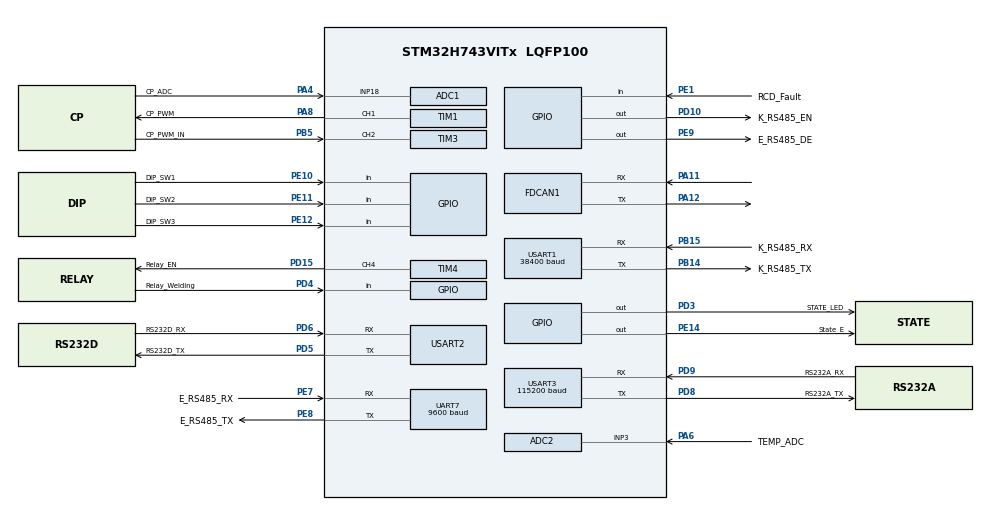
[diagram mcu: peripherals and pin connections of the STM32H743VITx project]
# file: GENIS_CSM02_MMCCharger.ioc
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ADC1.Channel-0\#ChannelRegularConversion=ADC_CHANNEL_18
ADC1.NbrOfConversionFlag=1
ADC1.OffsetNumber-0\#ChannelRegularConversion=ADC_OFFSET_NONE
ADC1.OffsetSignedSaturation-0\#ChannelRegularConversion=DISABLE
ADC1.Rank-0\#ChannelRegularConversion=1
ADC1.SamplingTime-0\#ChannelRegularConversion=ADC_SAMPLETIME_810CYCLES_5
ADC1.master=1
ADC2.Channel-6\#ChannelRegularConversion=ADC_CHANNEL_3
ADC2.ContinuousConvMode=DISABLE
ADC2.ConversionDataManagement=ADC_CONVERSIONDATA_DR
ADC2.DiscontinuousConvMode=DISABLE
ADC2.NbrOfConversionFlag=1
ADC2.OffsetNumber-6\#ChannelRegularConversion=ADC_OFFSET_NONE
ADC2.OffsetSignedSaturation-6\#ChannelRegularConversion=DISABLE
ADC2.Overrun=ADC_OVR_DATA_PRESERVED
ADC2.Rank-6\#ChannelRegularConversion=1
ADC2.SamplingTime-6\#ChannelRegularConversion=ADC_SAMPLETIME_810CYCLES_5
CORTEX_M7.AccessPermission_Spec=MPU_REGION_FULL_ACCESS
CORTEX_M7.BaseAddress_Spec=0x30000000
CORTEX_M7.CPU_DCache=Enabled
CORTEX_M7.CPU_ICache=Enabled
CORTEX_M7.IsShareable_Spec=MPU_ACCESS_NOT_SHAREABLE
CORTEX_M7.Size_Spec=MPU_REGION_SIZE_256KB
CORTEX_M7.SubRegionDisable_Spec=0x00
CORTEX_M7.TypeExtField_Spec=MPU_TEX_LEVEL1
CORTEX_M7.default_mode_Activation=1
FDCAN1.AutoRetransmission=ENABLE
FDCAN1.CalculateBaudRateNominal=500000
FDCAN1.CalculateTimeBitNominal=2000
FDCAN1.CalculateTimeQuantumNominal=200.0
FDCAN1.DataPrescaler=15
FDCAN1.DataSyncJumpWidth=1
FDCAN1.DataTimeSeg1=5
FDCAN1.DataTimeSeg2=4
FDCAN1.ExtFiltersNbr=1
FDCAN1.Mode=FDCAN_MODE_NORMAL
FDCAN1.NominalPrescaler=15
FDCAN1.NominalSyncJumpWidth=1
FDCAN1.NominalTimeSeg1=5
FDCAN1.NominalTimeSeg2=4
FDCAN1.ProtocolException=ENABLE
FDCAN1.RxFifo0ElmtsNbr=1
FDCAN1.StdFiltersNbr=0
FDCAN1.TxBuffersNbr=1
FDCAN1.TxFifoQueueElmtsNbr=1
FREERTOS.Tasks01=defaultTask,24,2048,StartDefaultTask,Default,NULL,Dynamic,NULL,NULL;Task_CANTx,8,2048,CANTxControl_Task,Default,NULL,Dynamic,NULL,NULL;Task_CANRx,8,2048,CANRxControl_Task,Default,NULL,Dynamic,NULL,NULL
FREERTOS.configCHECK_FOR_STACK_OVERFLOW=2
FREERTOS.configENABLE_FPU=1
FREERTOS.configTOTAL_HEAP_SIZE=102768
FREERTOS.configUSE_NEWLIB_REENTRANT=1
Mcu.Family=STM32H7
Mcu.Name=STM32H743VITx
Mcu.Package=LQFP100
NVIC.ADC_IRQn=true\:5\:0\:false\:false\:true\:true\:true\:true\:true
NVIC.FDCAN1_IT0_IRQn=true\:5\:0\:false\:false\:true\:true\:true\:true\:true
NVIC.FDCAN1_IT1_IRQn=true\:5\:0\:false\:false\:true\:true\:true\:true\:true
NVIC.FDCAN_CAL_IRQn=true\:5\:0\:false\:false\:true\:true\:true\:true\:true
NVIC.PriorityGroup=NVIC_PRIORITYGROUP_4
NVIC.TIM2_IRQn=true\:15\:0\:false\:false\:true\:false\:false\:true\:true
NVIC.TimeBase=TIM2_IRQn
NVIC.TimeBaseIP=TIM2
NVIC.UART7_IRQn=true\:5\:0\:false\:false\:true\:true\:true\:true\:true
NVIC.USART1_IRQn=true\:5\:0\:false\:false\:true\:true\:true\:true\:true
NVIC.USART2_IRQn=true\:5\:0\:true\:false\:true\:true\:true\:true\:true
NVIC.USART3_IRQn=true\:5\:0\:false\:false\:true\:true\:true\:true\:true
PA11.Mode=FDCAN_Activate
PA11.Signal=FDCAN1_RX
PA12.Mode=FDCAN_Activate
PA12.Signal=FDCAN1_TX
PA13\ (JTMS/SWDIO).Mode=JTAG_5_pins
PA13\ (JTMS/SWDIO).Signal=DEBUG_JTMS-SWDIO
PA14\ (JTCK/SWCLK).Mode=JTAG_5_pins
PA14\ (JTCK/SWCLK).Signal=DEBUG_JTCK-SWCLK
PA15\ (JTDI).Mode=JTAG_5_pins
PA15\ (JTDI).Signal=DEBUG_JTDI
PA4.GPIO_Label=CP_ADC
PA4.Signal=ADCx_INP18
PA6.GPIO_Label=TEMP_ADC
PA6.Signal=ADCx_INP3
PA8.GPIO_Label=CP_PWM
PA8.Signal=S_TIM1_CH1
PB14.GPIO_Label=K_RS485_TX
PB14.Mode=Asynchronous
PB14.Signal=USART1_TX
PB15.GPIO_Label=K_RS485_RX
PB15.Mode=Asynchronous
PB15.Signal=USART1_RX
PB3\ (JTDO/TRACESWO).Mode=JTAG_5_pins
PB3\ (JTDO/TRACESWO).Signal=DEBUG_JTDO-SWO
PB4\ (NJTRST).Mode=JTAG_5_pins
PB4\ (NJTRST).Signal=DEBUG_JTRST
PB5.GPIO_Label=CP_PWM_IN
PB5.Signal=S_TIM3_CH2
PC14-OSC32_IN\ (OSC32_IN).Mode=LSE-External-Oscillator
PC14-OSC32_IN\ (OSC32_IN).Signal=RCC_OSC32_IN
PC15-OSC32_OUT\ (OSC32_OUT).Mode=LSE-External-Oscillator
PC15-OSC32_OUT\ (OSC32_OUT).Signal=RCC_OSC32_OUT
PD10.GPIO_Label=K_RS485_EN
PD10.Signal=GPIO_Output
PD15.GPIO_Label=Relay_EN
PD15.Signal=S_TIM4_CH4
PD3.GPIO_Label=STATE_LED
PD3.Signal=GPIO_Output
PD4.GPIO_Label=Relay_Welding
PD4.Signal=GPIO_Input
PD5.GPIO_Label=RS232D_TX
PD5.Mode=Asynchronous
PD5.Signal=USART2_TX
PD6.GPIO_Label=RS232D_RX
PD6.Mode=Asynchronous
PD6.Signal=USART2_RX
PD8.GPIO_Label=RS232A_TX
PD8.Mode=Asynchronous
PD8.Signal=USART3_TX
PD9.GPIO_Label=RS232A_RX
PD9.Mode=Asynchronous
PD9.Signal=USART3_RX
PE1.GPIO_Label=RCD_Fault
PE1.GPIO_PuPd=GPIO_PULLDOWN
PE1.Signal=GPIO_Input
PE10.GPIO_Label=DIP_SW1
PE10.Signal=GPIO_Input
PE11.GPIO_Label=DIP_SW2
PE11.Signal=GPIO_Input
PE12.GPIO_Label=DIP_SW3
PE12.Signal=GPIO_Input
PE14.GPIO_Label=State_E
PE14.Signal=GPIO_Output
PE7.GPIO_Label=E_RS485_RX
PE7.Mode=Asynchronous
PE7.Signal=UART7_RX
PE8.GPIO_Label=E_RS485_TX
PE8.Mode=Asynchronous
PE8.Signal=UART7_TX
PE9.GPIO_Label=E_RS485_DE
PE9.Signal=GPIO_Output
PH0-OSC_IN\ (PH0).Mode=HSE-External-Oscillator
PH0-OSC_IN\ (PH0).Signal=RCC_OSC_IN
PH1-OSC_OUT\ (PH1).Mode=HSE-External-Oscillator
PH1-OSC_OUT\ (PH1).Signal=RCC_OSC_OUT
ProjectManager.HeapSize=0x200
ProjectManager.StackSize=0x400
ProjectManager.TargetToolchain=STM32CubeIDE
RCC.ADCFreq_Value=75000000
RCC.APB1Freq_Value=120000000
RCC.APB2Freq_Value=120000000
RCC.APB3Freq_Value=120000000
RCC.APB4Freq_Value=120000000
RCC.CortexFreq_Value=480000000
RCC.D1PPRE=RCC_APB3_DIV2
RCC.D2PPRE1=RCC_APB1_DIV2
RCC.D2PPRE2=RCC_APB2_DIV2
RCC.D3PPRE=RCC_APB4_DIV2
RCC.DIVM1=1
RCC.DIVM2=1
RCC.DIVN1=60
RCC.DIVN2=9
RCC.DIVQ1=8
RCC.FDCANCLockSelection=RCC_FDCANCLKSOURCE_PLL2
RCC.HCLKFreq_Value=240000000
RCC.HPRE=RCC_HCLK_DIV2
RCC.HSE_VALUE=16000000
RCC.PLL2FRACN=3072
RCC.PLLFRACN=0
RCC.PLLSourceVirtual=RCC_PLLSOURCE_HSE
RCC.PWR_Regulator_Voltage_Scale=PWR_REGULATOR_VOLTAGE_SCALE0
RCC.RTCClockSelection=RCC_RTCCLKSOURCE_LSE
RCC.SYSCLKFreq_VALUE=480000000
RCC.SYSCLKSource=RCC_SYSCLKSOURCE_PLLCLK
RCC.USBFreq_Value=120000000
SH.ADCx_INP18.0=ADC1_INP18,IN18-Single-Ended
SH.ADCx_INP3.0=ADC2_INP3,IN3-Single-Ended
SH.S_TIM1_CH1.0=TIM1_CH1,PWM Generation1 CH1
SH.S_TIM3_CH2.0=TIM3_CH2,PWM_Input_2
SH.S_TIM4_CH4.0=TIM4_CH4,PWM Generation4 CH4
TIM1.Channel-PWM\ Generation1\ CH1=TIM_CHANNEL_1
TIM1.Period=998
TIM1.Prescaler=240
TIM4.Channel-PWM\ Generation4\ CH4=TIM_CHANNEL_4
TIM4.Period=1000-1
TIM4.Prescaler=12-1
TIM4.Pulse-PWM\ Generation4\ CH4=0
TIM4.TIM_MasterOutputTrigger=TIM_TRGO_UPDATE
UART7.BaudRate=9600
USART1.BaudRate=38400
USART1.VirtualMode-Asynchronous=VM_ASYNC
USART2.VirtualMode-Asynchronous=VM_ASYNC
USART3.BaudRate=115200
USART3.VirtualMode-Asynchronous=VM_ASYNC
VP_FREERTOS_VS_CMSIS_V2.Mode=CMSIS_V2
VP_RTC_VS_RTC_Activate.Mode=RTC_Enabled
VP_SYS_VS_tim2.Mode=TIM2
board=custom

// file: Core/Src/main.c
/* USER CODE BEGIN Header */
/**
  ******************************************************************************
  * @file           : main.c
  * @brief          : Main program body
  ******************************************************************************
  * @attention
  *
  * Copyright (c) 2025 STMicroelectronics.
  * All rights reserved.
  *
  * This software is licensed under terms that can be found in the LICENSE file
  * in the root directory of this software component.
  * If no LICENSE file comes with this software, it is provided AS-IS.
  *
  ******************************************************************************
  */
/* USER CODE END Header */
#include "main.h"
#include "cmsis_os.h"
#include "adc.h"
#include "fdcan.h"
#include "rtc.h"
#include "tim.h"
#include "usart.h"
#include "gpio.h"

/* USER CODE BEGIN Includes */
#include "../Driver/UART.h"
/* USER CODE END Includes */

void SystemClock_Config(void);
void PeriphCommonClock_Config(void);
static void MPU_Config(void);
void MX_FREERTOS_Init(void);

int main(void)
{

  /* MPU Configuration--------------------------------------------------------*/
  MPU_Config();

  /* Enable the CPU Cache */

  /* Enable I-Cache---------------------------------------------------------*/
  SCB_EnableICache();

  /* Enable D-Cache---------------------------------------------------------*/
  SCB_EnableDCache();

  /* MCU Configuration--------------------------------------------------------*/

  /* Reset of all peripherals, Initializes the Flash interface and the Systick. */
  HAL_Init();

  /* USER CODE BEGIN Init */
  HAL_UART_Receive_IT(&huart2, &uart2RxData, 1);
  /* USER CODE END Init */

  /* Configure the system clock */
  SystemClock_Config();

  /* Configure the peripherals common clocks */
  PeriphCommonClock_Config();

  /* Initialize all configured peripherals */
  MX_GPIO_Init();
  MX_UART7_Init();
  MX_USART1_UART_Init();
  MX_USART2_UART_Init();
  MX_USART3_UART_Init();
  MX_TIM4_Init();
  MX_ADC1_Init();
  MX_TIM1_Init();
  MX_TIM3_Init();
  MX_RTC_Init();
  MX_ADC2_Init();
  MX_FDCAN1_Init();

  /* Init scheduler */
  osKernelInitialize();

  /* Call init function for freertos objects (in cmsis_os2.c) */
  MX_FREERTOS_Init();

  /* Start scheduler */
  osKernelStart();

  /* We should never get here as control is now taken by the scheduler */

  /* Infinite loop */
  while (1)
  {

  }
}

void SystemClock_Config(void)
{
  RCC_OscInitTypeDef RCC_OscInitStruct = {0};
  RCC_ClkInitTypeDef RCC_ClkInitStruct = {0};

  /** Supply configuration update enable
  */
  HAL_PWREx_ConfigSupply(PWR_LDO_SUPPLY);

  /** Configure the main internal regulator output voltage
  */
  __HAL_PWR_VOLTAGESCALING_CONFIG(PWR_REGULATOR_VOLTAGE_SCALE0);

  while(!__HAL_PWR_GET_FLAG(PWR_FLAG_VOSRDY)) {}

  /** Configure LSE Drive Capability
  */
  HAL_PWR_EnableBkUpAccess();
  __HAL_RCC_LSEDRIVE_CONFIG(RCC_LSEDRIVE_LOW);

  /** Initializes the RCC Oscillators according to the specified parameters
  * in the RCC_OscInitTypeDef structure.
  */
  RCC_OscInitStruct.OscillatorType = RCC_OSCILLATORTYPE_HSE|RCC_OSCILLATORTYPE_LSE;
  RCC_OscInitStruct.HSEState = RCC_HSE_ON;
  RCC_OscInitStruct.LSEState = RCC_LSE_ON;
  RCC_OscInitStruct.PLL.PLLState = RCC_PLL_ON;
  RCC_OscInitStruct.PLL.PLLSource = RCC_PLLSOURCE_HSE;
  RCC_OscInitStruct.PLL.PLLM = 1;
  RCC_OscInitStruct.PLL.PLLN = 60;
  RCC_OscInitStruct.PLL.PLLP = 2;
  RCC_OscInitStruct.PLL.PLLQ = 8;
  RCC_OscInitStruct.PLL.PLLR = 2;
  RCC_OscInitStruct.PLL.PLLRGE = RCC_PLL1VCIRANGE_3;
  RCC_OscInitStruct.PLL.PLLVCOSEL = RCC_PLL1VCOWIDE;
  RCC_OscInitStruct.PLL.PLLFRACN = 0;
  if (HAL_RCC_OscConfig(&RCC_OscInitStruct) != HAL_OK)
  {
    Error_Handler();
  }

  /** Initializes the CPU, AHB and APB buses clocks
  */
  RCC_ClkInitStruct.ClockType = RCC_CLOCKTYPE_HCLK|RCC_CLOCKTYPE_SYSCLK
                              |RCC_CLOCKTYPE_PCLK1|RCC_CLOCKTYPE_PCLK2
                              |RCC_CLOCKTYPE_D3PCLK1|RCC_CLOCKTYPE_D1PCLK1;
  RCC_ClkInitStruct.SYSCLKSource = RCC_SYSCLKSOURCE_PLLCLK;
  RCC_ClkInitStruct.SYSCLKDivider = RCC_SYSCLK_DIV1;
  RCC_ClkInitStruct.AHBCLKDivider = RCC_HCLK_DIV2;
  RCC_ClkInitStruct.APB3CLKDivider = RCC_APB3_DIV2;
  RCC_ClkInitStruct.APB1CLKDivider = RCC_APB1_DIV2;
  RCC_ClkInitStruct.APB2CLKDivider = RCC_APB2_DIV2;
  RCC_ClkInitStruct.APB4CLKDivider = RCC_APB4_DIV2;

  if (HAL_RCC_ClockConfig(&RCC_ClkInitStruct, FLASH_LATENCY_4) != HAL_OK)
  {
    Error_Handler();
  }
}

void PeriphCommonClock_Config(void)
{
  RCC_PeriphCLKInitTypeDef PeriphClkInitStruct = {0};

  /** Initializes the peripherals clock
  */
  PeriphClkInitStruct.PeriphClockSelection = RCC_PERIPHCLK_ADC|RCC_PERIPHCLK_FDCAN;
  PeriphClkInitStruct.PLL2.PLL2M = 1;
  PeriphClkInitStruct.PLL2.PLL2N = 9;
  PeriphClkInitStruct.PLL2.PLL2P = 2;
  PeriphClkInitStruct.PLL2.PLL2Q = 2;
  PeriphClkInitStruct.PLL2.PLL2R = 2;
  PeriphClkInitStruct.PLL2.PLL2RGE = RCC_PLL2VCIRANGE_3;
  PeriphClkInitStruct.PLL2.PLL2VCOSEL = RCC_PLL2VCOMEDIUM;
  PeriphClkInitStruct.PLL2.PLL2FRACN = 3072;
  PeriphClkInitStruct.FdcanClockSelection = RCC_FDCANCLKSOURCE_PLL2;
  PeriphClkInitStruct.AdcClockSelection = RCC_ADCCLKSOURCE_PLL2;
  if (HAL_RCCEx_PeriphCLKConfig(&PeriphClkInitStruct) != HAL_OK)
  {
    Error_Handler();
  }
}

 /* MPU Configuration */

void MPU_Config(void)
{
  MPU_Region_InitTypeDef MPU_InitStruct = {0};

  /* Disables the MPU */
  HAL_MPU_Disable();

  /** Initializes and configures the Region and the memory to be protected
  */
  MPU_InitStruct.Enable = MPU_REGION_ENABLE;
  MPU_InitStruct.Number = MPU_REGION_NUMBER0;
  MPU_InitStruct.BaseAddress = 0x30000000;
  MPU_InitStruct.Size = MPU_REGION_SIZE_256KB;
  MPU_InitStruct.SubRegionDisable = 0x00;
  MPU_InitStruct.TypeExtField = MPU_TEX_LEVEL1;
  MPU_InitStruct.AccessPermission = MPU_REGION_FULL_ACCESS;
  MPU_InitStruct.DisableExec = MPU_INSTRUCTION_ACCESS_DISABLE;
  MPU_InitStruct.IsShareable = MPU_ACCESS_NOT_SHAREABLE;
  MPU_InitStruct.IsCacheable = MPU_ACCESS_NOT_CACHEABLE;
  MPU_InitStruct.IsBufferable = MPU_ACCESS_NOT_BUFFERABLE;

  HAL_MPU_ConfigRegion(&MPU_InitStruct);
  /* Enables the MPU */
  HAL_MPU_Enable(MPU_PRIVILEGED_DEFAULT);

}

void HAL_TIM_PeriodElapsedCallback(TIM_HandleTypeDef *htim)
{
  if (htim->Instance == TIM2)
  {
    HAL_IncTick();
  }
}

void Error_Handler(void)
{
  __disable_irq();
  while (1)
  {
  }
}

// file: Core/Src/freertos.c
/* USER CODE BEGIN Header */
/**
  ******************************************************************************
  * File Name          : freertos.c
  * Description        : Code for freertos applications
  ******************************************************************************
  * @attention
  *
  * Copyright (c) 2025 STMicroelectronics.
  * All rights reserved.
  *
  * This software is licensed under terms that can be found in the LICENSE file
  * in the root directory of this software component.
  * If no LICENSE file comes with this software, it is provided AS-IS.
  *
  ******************************************************************************
  */
/* USER CODE END Header */

#include "FreeRTOS.h"
#include "task.h"
#include "main.h"
#include "cmsis_os.h"

/* USER CODE BEGIN Includes */
#include "../Controller/CANController.h"
#include "../Genis/Charger/Charger.h"
/* USER CODE END Includes */

/* USER CODE BEGIN Variables */
  GenisCsm_ChargerType Charger = {0};
/* USER CODE END Variables */
/* Definitions for defaultTask */
osThreadId_t defaultTaskHandle;
const osThreadAttr_t defaultTask_attributes = {
  .name = "defaultTask",
  .stack_size = 2048 * 4,
  .priority = (osPriority_t) osPriorityNormal,
};
/* Definitions for Task_CANTx */
osThreadId_t Task_CANTxHandle;
const osThreadAttr_t Task_CANTx_attributes = {
  .name = "Task_CANTx",
  .stack_size = 2048 * 4,
  .priority = (osPriority_t) osPriorityLow,
};
/* Definitions for Task_CANRx */
osThreadId_t Task_CANRxHandle;
const osThreadAttr_t Task_CANRx_attributes = {
  .name = "Task_CANRx",
  .stack_size = 2048 * 4,
  .priority = (osPriority_t) osPriorityLow,
};

void StartDefaultTask(void *argument);
void CANTxControl_Task(void *argument);
void CANRxControl_Task(void *argument);

void MX_FREERTOS_Init(void); /* (MISRA C 2004 rule 8.1) */

/* Hook prototypes */
void vApplicationStackOverflowHook(xTaskHandle xTask, signed char *pcTaskName);

/* USER CODE BEGIN 4 */
void vApplicationStackOverflowHook(xTaskHandle xTask, signed char *pcTaskName)
{
   /* Run time stack overflow checking is performed if
   configCHECK_FOR_STACK_OVERFLOW is defined to 1 or 2. This hook function is
   called if a stack overflow is detected. */
}
/* USER CODE END 4 */

void MX_FREERTOS_Init(void) {

  /* Create the thread(s) */
  /* creation of defaultTask */
  defaultTaskHandle = osThreadNew(StartDefaultTask, NULL, &defaultTask_attributes);

  /* creation of Task_CANTx */
  Task_CANTxHandle = osThreadNew(CANTxControl_Task, NULL, &Task_CANTx_attributes);

  /* creation of Task_CANRx */
  Task_CANRxHandle = osThreadNew(CANRxControl_Task, NULL, &Task_CANRx_attributes);

}

void StartDefaultTask(void *argument)
{
  /* USER CODE BEGIN StartDefaultTask */

  GenisCsm_Charger_Init(&Charger);
  /* Infinite loop */
  for(;;)
  {
    GenisCsm_Charger_MainFunction(&Charger);
    osDelay(100);
  }
  /* USER CODE END StartDefaultTask */
}

void CANTxControl_Task(void *argument)
{
  /* USER CODE BEGIN CANTxControl_Task */
  FDCAN_Filter_Config_mask32_Init();
  /* Infinite loop */
  for(;;)
  {
    App_CanTxMainFunction(&Charger);
    osDelay(1);
  }
  /* USER CODE END CANTxControl_Task */
}

void CANRxControl_Task(void *argument)
{
  /* USER CODE BEGIN CANRxControl_Task */
  /* Infinite loop */
  for(;;)
  {
    App_CanRxMainFunction(&Charger);
    osDelay(1);
  }
  /* USER CODE END CANRxControl_Task */
}
